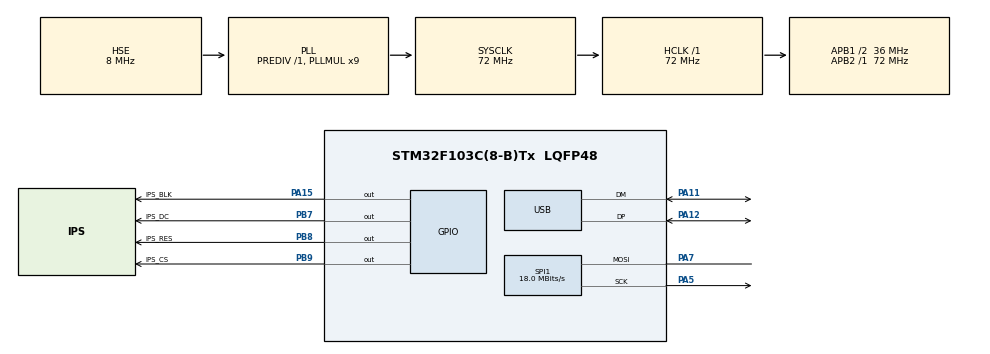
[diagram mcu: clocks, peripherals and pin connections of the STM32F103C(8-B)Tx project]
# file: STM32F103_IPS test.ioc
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Mcu.Family=STM32F1
Mcu.Name=STM32F103C(8-B)Tx
Mcu.Package=LQFP48
NVIC.PriorityGroup=NVIC_PRIORITYGROUP_4
PA11.Mode=Device
PA11.Signal=USB_DM
PA12.Mode=Device
PA12.Signal=USB_DP
PA13.Mode=Serial_Wire
PA13.Signal=SYS_JTMS-SWDIO
PA14.Mode=Serial_Wire
PA14.Signal=SYS_JTCK-SWCLK
PA15.GPIO_Label=IPS_BLK
PA15.Signal=GPIO_Output
PA5.Mode=Simplex_Bidirectional_Master
PA5.Signal=SPI1_SCK
PA7.Mode=Simplex_Bidirectional_Master
PA7.Signal=SPI1_MOSI
PB7.GPIO_Label=IPS_DC
PB7.Signal=GPIO_Output
PB8.GPIO_Label=IPS_RES
PB8.Signal=GPIO_Output
PB9.GPIO_Label=IPS_CS
PB9.PinState=GPIO_PIN_SET
PB9.Signal=GPIO_Output
PD0-OSC_IN.Mode=HSE-External-Oscillator
PD0-OSC_IN.Signal=RCC_OSC_IN
PD1-OSC_OUT.Mode=HSE-External-Oscillator
PD1-OSC_OUT.Signal=RCC_OSC_OUT
ProjectManager.HeapSize=0x200
ProjectManager.StackSize=0x400
ProjectManager.TargetToolchain=MDK-ARM V5.27
RCC.ADCPresc=RCC_ADCPCLK2_DIV6
RCC.AHBFreq_Value=72000000
RCC.APB1CLKDivider=RCC_HCLK_DIV2
RCC.APB1Freq_Value=36000000
RCC.APB1TimFreq_Value=72000000
RCC.APB2Freq_Value=72000000
RCC.APB2TimFreq_Value=72000000
RCC.HCLKFreq_Value=72000000
RCC.PLLMUL=RCC_PLL_MUL9
RCC.PLLSourceVirtual=RCC_PLLSOURCE_HSE
RCC.SYSCLKFreq_VALUE=72000000
RCC.SYSCLKSource=RCC_SYSCLKSOURCE_PLLCLK
RCC.USBFreq_Value=48000000
RCC.USBPrescaler=RCC_USBCLKSOURCE_PLL_DIV1_5
RTC.Format=RTC_FORMAT_BCD
SPI1.BaudRatePrescaler=SPI_BAUDRATEPRESCALER_4
SPI1.CLKPhase=SPI_PHASE_1EDGE
SPI1.CLKPolarity=SPI_POLARITY_LOW
SPI1.CalculateBaudRate=18.0 MBits/s
SPI1.Direction=SPI_DIRECTION_1LINE
SPI1.Mode=SPI_MODE_MASTER
SPI1.VirtualType=VM_MASTER
VP_RTC_VS_RTC_Activate.Mode=RTC_Enabled
VP_RTC_VS_RTC_Calendar.Mode=RTC_Calendar
board=custom

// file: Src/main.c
/* USER CODE BEGIN Header */
/**
  ******************************************************************************
  * @file           : main.c
  * @brief          : Main program body
  ******************************************************************************
  * @attention
  *
  * <h2><center>&copy; Copyright (c) 2021 STMicroelectronics.
  * All rights reserved.</center></h2>
  *
  * This software component is licensed by ST under BSD 3-Clause license,
  * the "License"; You may not use this file except in compliance with the
  * License. You may obtain a copy of the License at:
  *                        opensource.org/licenses/BSD-3-Clause
  *
  ******************************************************************************
  */
/* USER CODE END Header */
#include "main.h"

/* USER CODE BEGIN Includes */
#include "lcd.h"
#include "gui.h"
#include "test.h"
/* USER CODE END Includes */

RTC_HandleTypeDef hrtc;

SPI_HandleTypeDef hspi1;

PCD_HandleTypeDef hpcd_USB_FS;

void SystemClock_Config(void);
static void MX_GPIO_Init(void);
static void MX_SPI1_Init(void);
static void MX_RTC_Init(void);
static void MX_USB_PCD_Init(void);

int main(void)
{

  /* MCU Configuration--------------------------------------------------------*/

  /* Reset of all peripherals, Initializes the Flash interface and the Systick. */
  HAL_Init();

  /* Configure the system clock */
  SystemClock_Config();

  /* Initialize all configured peripherals */
  MX_GPIO_Init();
  MX_SPI1_Init();
  MX_RTC_Init();
  MX_USB_PCD_Init();
  /* USER CODE BEGIN 2 */
	LCD_Init();
  /* USER CODE END 2 */

  /* Infinite loop */
  /* USER CODE BEGIN WHILE */
  while (1)
  {
	main_test(); 		//测试主界面
	menu_test();     //3D菜单显示测试
	Test_Color();  		//简单刷屏填充测试
	Test_FillRec();		//GUI矩形绘图测试
	Test_Circle(); 		//GUI画圆测试
//	Test_Triangle();    //GUI三角形绘图测试
//	English_Font_test();//英文字体示例测试
//	Chinese_Font_test();//中文字体示例测试
	Pic_test();			//图片显示示例测试
//	Rotate_Test();   //旋转显示测试

    /* USER CODE END WHILE */

  }
}

void SystemClock_Config(void)
{
  RCC_OscInitTypeDef RCC_OscInitStruct = {0};
  RCC_ClkInitTypeDef RCC_ClkInitStruct = {0};
  RCC_PeriphCLKInitTypeDef PeriphClkInit = {0};

  /** Initializes the RCC Oscillators according to the specified parameters
  * in the RCC_OscInitTypeDef structure.
  */
  RCC_OscInitStruct.OscillatorType = RCC_OSCILLATORTYPE_LSI|RCC_OSCILLATORTYPE_HSE;
  RCC_OscInitStruct.HSEState = RCC_HSE_ON;
  RCC_OscInitStruct.HSEPredivValue = RCC_HSE_PREDIV_DIV1;
  RCC_OscInitStruct.HSIState = RCC_HSI_ON;
  RCC_OscInitStruct.LSIState = RCC_LSI_ON;
  RCC_OscInitStruct.PLL.PLLState = RCC_PLL_ON;
  RCC_OscInitStruct.PLL.PLLSource = RCC_PLLSOURCE_HSE;
  RCC_OscInitStruct.PLL.PLLMUL = RCC_PLL_MUL9;
  if (HAL_RCC_OscConfig(&RCC_OscInitStruct) != HAL_OK)
  {
    Error_Handler();
  }
  /** Initializes the CPU, AHB and APB buses clocks
  */
  RCC_ClkInitStruct.ClockType = RCC_CLOCKTYPE_HCLK|RCC_CLOCKTYPE_SYSCLK
                              |RCC_CLOCKTYPE_PCLK1|RCC_CLOCKTYPE_PCLK2;
  RCC_ClkInitStruct.SYSCLKSource = RCC_SYSCLKSOURCE_PLLCLK;
  RCC_ClkInitStruct.AHBCLKDivider = RCC_SYSCLK_DIV1;
  RCC_ClkInitStruct.APB1CLKDivider = RCC_HCLK_DIV2;
  RCC_ClkInitStruct.APB2CLKDivider = RCC_HCLK_DIV1;

  if (HAL_RCC_ClockConfig(&RCC_ClkInitStruct, FLASH_LATENCY_2) != HAL_OK)
  {
    Error_Handler();
  }
  PeriphClkInit.PeriphClockSelection = RCC_PERIPHCLK_RTC|RCC_PERIPHCLK_USB;
  PeriphClkInit.RTCClockSelection = RCC_RTCCLKSOURCE_LSI;
  PeriphClkInit.UsbClockSelection = RCC_USBCLKSOURCE_PLL_DIV1_5;
  if (HAL_RCCEx_PeriphCLKConfig(&PeriphClkInit) != HAL_OK)
  {
    Error_Handler();
  }
}

static void MX_RTC_Init(void)
{

  RTC_TimeTypeDef sTime = {0};
  RTC_DateTypeDef DateToUpdate = {0};

  /** Initialize RTC Only
  */
  hrtc.Instance = RTC;
  hrtc.Init.AsynchPrediv = RTC_AUTO_1_SECOND;
  hrtc.Init.OutPut = RTC_OUTPUTSOURCE_ALARM;
  if (HAL_RTC_Init(&hrtc) != HAL_OK)
  {
    Error_Handler();
  }

  /** Initialize RTC and set the Time and Date
  */
  sTime.Hours = 0x0;
  sTime.Minutes = 0x0;
  sTime.Seconds = 0x0;

  if (HAL_RTC_SetTime(&hrtc, &sTime, RTC_FORMAT_BCD) != HAL_OK)
  {
    Error_Handler();
  }
  DateToUpdate.WeekDay = RTC_WEEKDAY_MONDAY;
  DateToUpdate.Month = RTC_MONTH_JANUARY;
  DateToUpdate.Date = 0x1;
  DateToUpdate.Year = 0x0;

  if (HAL_RTC_SetDate(&hrtc, &DateToUpdate, RTC_FORMAT_BCD) != HAL_OK)
  {
    Error_Handler();
  }

}

static void MX_SPI1_Init(void)
{

  /* SPI1 parameter configuration*/
  hspi1.Instance = SPI1;
  hspi1.Init.Mode = SPI_MODE_MASTER;
  hspi1.Init.Direction = SPI_DIRECTION_1LINE;
  hspi1.Init.DataSize = SPI_DATASIZE_8BIT;
  hspi1.Init.CLKPolarity = SPI_POLARITY_LOW;
  hspi1.Init.CLKPhase = SPI_PHASE_1EDGE;
  hspi1.Init.NSS = SPI_NSS_SOFT;
  hspi1.Init.BaudRatePrescaler = SPI_BAUDRATEPRESCALER_4;
  hspi1.Init.FirstBit = SPI_FIRSTBIT_MSB;
  hspi1.Init.TIMode = SPI_TIMODE_DISABLE;
  hspi1.Init.CRCCalculation = SPI_CRCCALCULATION_DISABLE;
  hspi1.Init.CRCPolynomial = 10;
  if (HAL_SPI_Init(&hspi1) != HAL_OK)
  {
    Error_Handler();
  }

}

static void MX_USB_PCD_Init(void)
{

  hpcd_USB_FS.Instance = USB;
  hpcd_USB_FS.Init.dev_endpoints = 8;
  hpcd_USB_FS.Init.speed = PCD_SPEED_FULL;
  hpcd_USB_FS.Init.low_power_enable = DISABLE;
  hpcd_USB_FS.Init.lpm_enable = DISABLE;
  hpcd_USB_FS.Init.battery_charging_enable = DISABLE;
  if (HAL_PCD_Init(&hpcd_USB_FS) != HAL_OK)
  {
    Error_Handler();
  }

}

static void MX_GPIO_Init(void)
{
  GPIO_InitTypeDef GPIO_InitStruct = {0};

  /* GPIO Ports Clock Enable */
  __HAL_RCC_GPIOD_CLK_ENABLE();
  __HAL_RCC_GPIOA_CLK_ENABLE();
  __HAL_RCC_GPIOB_CLK_ENABLE();

  /*Configure GPIO pin Output Level */
  HAL_GPIO_WritePin(IPS_BLK_GPIO_Port, IPS_BLK_Pin, GPIO_PIN_RESET);

  /*Configure GPIO pin Output Level */
  HAL_GPIO_WritePin(GPIOB, IPS_DC_Pin|IPS_RES_Pin, GPIO_PIN_RESET);

  /*Configure GPIO pin Output Level */
  HAL_GPIO_WritePin(IPS_CS_GPIO_Port, IPS_CS_Pin, GPIO_PIN_SET);

  /*Configure GPIO pin : IPS_BLK_Pin */
  GPIO_InitStruct.Pin = IPS_BLK_Pin;
  GPIO_InitStruct.Mode = GPIO_MODE_OUTPUT_PP;
  GPIO_InitStruct.Pull = GPIO_NOPULL;
  GPIO_InitStruct.Speed = GPIO_SPEED_FREQ_LOW;
  HAL_GPIO_Init(IPS_BLK_GPIO_Port, &GPIO_InitStruct);

  /*Configure GPIO pins : IPS_DC_Pin IPS_RES_Pin IPS_CS_Pin */
  GPIO_InitStruct.Pin = IPS_DC_Pin|IPS_RES_Pin|IPS_CS_Pin;
  GPIO_InitStruct.Mode = GPIO_MODE_OUTPUT_PP;
  GPIO_InitStruct.Pull = GPIO_NOPULL;
  GPIO_InitStruct.Speed = GPIO_SPEED_FREQ_LOW;
  HAL_GPIO_Init(GPIOB, &GPIO_InitStruct);

}

void Error_Handler(void)
{
}

/************************ (C) COPYRIGHT STMicroelectronics *****END OF FILE****/
